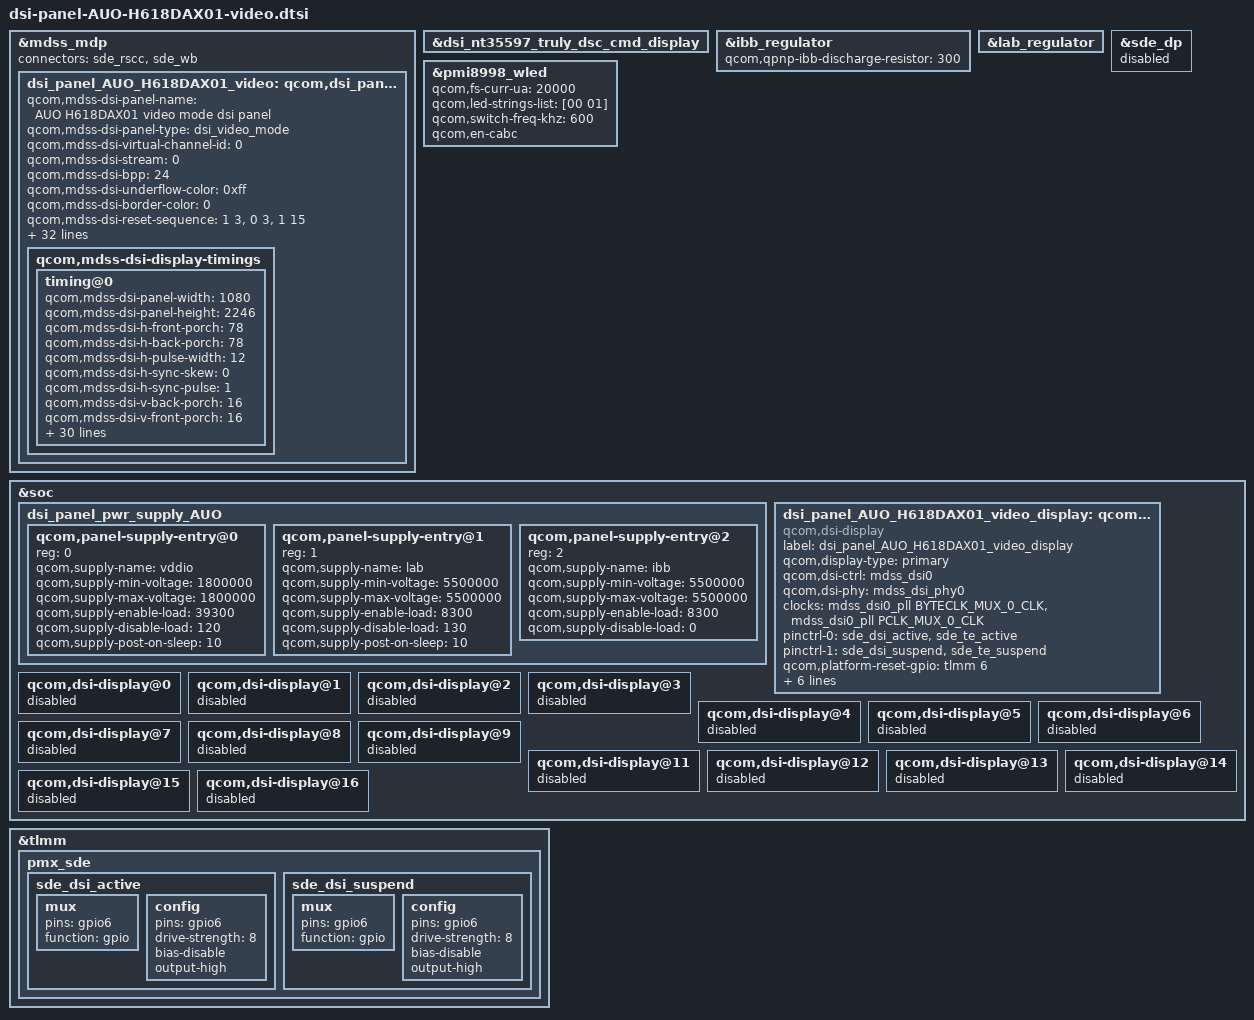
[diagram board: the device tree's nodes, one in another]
/* Copyright (c) 2017, The Linux Foundation. All rights reserved.
 *
 * This program is free software; you can redistribute it and/or modify
 * it under the terms of the GNU General Public License version 2 and
 * only version 2 as published by the Free Software Foundation.
 *
 * This program is distributed in the hope that it will be useful,
 * but WITHOUT ANY WARRANTY; without even the implied warranty of
 * MERCHANTABILITY or FITNESS FOR A PARTICULAR PURPOSE.  See the
 * GNU General Public License for more details.
 */

&mdss_mdp {
	dsi_panel_AUO_H618DAX01_video: qcom,dsi_panel_AUO_H618DAX01_video {
		qcom,mdss-dsi-panel-name =
				"AUO H618DAX01 video mode dsi panel";
		qcom,mdss-dsi-panel-type = "dsi_video_mode";  /* key flag to diff video/cmd, in dsi_panel.c */
		qcom,mdss-dsi-virtual-channel-id = <0>;
		qcom,mdss-dsi-stream = <0>;
		qcom,mdss-dsi-bpp = <24>;
		qcom,mdss-dsi-underflow-color = <0xff>;
		qcom,mdss-dsi-border-color = <0>;
		qcom,mdss-dsi-reset-sequence = <1 3>, <0 3>, <1 15>;  /* >1, >1, >10 */
		qcom,mdss-dsi-traffic-mode = "burst_mode";
		qcom,mdss-dsi-bllp-eof-power-mode;
		qcom,mdss-dsi-bllp-power-mode;
		qcom,mdss-dsi-lane-0-state;
		qcom,mdss-dsi-lane-1-state;
		qcom,mdss-dsi-lane-2-state;
		qcom,mdss-dsi-lane-3-state;
		qcom,mdss-dsi-lp11-init;
		qcom,mdss-dsi-bl-min-level = <1>;
		qcom,mdss-dsi-bl-max-level = <1023>;
		qcom,mdss-dsi-dma-trigger = "trigger_sw";
		qcom,mdss-dsi-mdp-trigger = "none";
		qcom,mdss-dsi-bl-pmic-control-type = "bl_ctrl_dcs";

		qcom,mdss-dsi-tx-eot-append;
		qcom,mdss-dsi-post-init-delay = <1>;

		qcom,mdss-pan-physical-width-dimension = <68>;
		qcom,mdss-pan-physical-height-dimension = <141>;

		qcom,panel-supply-entries = <&dsi_panel_pwr_supply_AUO>;
		qcom,mdss-dsi-mode-sel-gpio-state = "single_port";
		qcom,platform-reset-gpio = <&tlmm 6 0>;
		qcom,platform-te-gpio = <&tlmm 10 0>;
		qcom,mdss-dsi-t-clk-post = <0x0e>;
		qcom,mdss-dsi-t-clk-pre = <0x35>;
		qcom,mdss-dsi-panel-hdr-enabled;
		qcom,mdss-dsi-panel-hdr-color-primaries = <15150 15850 33950 15850 13200 34500 7500 3000>;
		qcom,mdss-dsi-panel-peak-brightness = <5000000>;
		qcom,mdss-dsi-panel-blackness-level = <3300>;
		qcom,ulps-enabled;
		qcom,suspend-ulps-enabled;

		qcom,mdss-dsi-display-timings {
			timing@0{
				qcom,mdss-dsi-panel-width = <1080>;
				qcom,mdss-dsi-panel-height = <2246>;
				qcom,mdss-dsi-h-front-porch = <78>;
				qcom,mdss-dsi-h-back-porch = <78>;
				qcom,mdss-dsi-h-pulse-width = <12>;
				qcom,mdss-dsi-h-sync-skew = <0>;
				qcom,mdss-dsi-h-sync-pulse = <1>;
				qcom,mdss-dsi-v-back-porch = <16>;
				qcom,mdss-dsi-v-front-porch = <16>;
				qcom,mdss-dsi-v-pulse-width = <2>;
				qcom,mdss-dsi-panel-framerate = <60>;
				qcom,mdss-dsi-h-left-border = <0>;
				qcom,mdss-dsi-h-right-border = <0>;
				qcom,mdss-dsi-v-top-border = <0>;
				qcom,mdss-dsi-v-bottom-border = <0>;
				qcom,mdss-dsi-on-command =[
					/* Enable Command2 */
					39 01 00 00 00 00 02 00 00
					39 01 00 00 00 00 04 FF 87 16 01
					/* Enable Focal Command */
					39 01 00 00 00 00 02 00 80
					39 01 00 00 00 00 03 FF 87 16
					/* Resolution 1080x2246  */
					39 01 00 00 00 00 02 00 00
					39 01 00 00 00 00 05 2A 00 00 04 37
					39 01 00 00 00 00 02 00 00
					39 01 00 00 00 00 05 2B 00 00 08 C5
					// PWM Freq. = 34.18K
					39 01 00 00 00 00 02 00 B0
					39 01 00 00 00 00 03 CA 00 00
					// PWM = 10bit
					39 01 00 00 00 00 02 00 B2
					39 01 00 00 00 00 02 CA 04
					// Dimming Frame = 32
					39 01 00 00 00 00 02 00 B5
					39 01 00 00 00 00 02 CA 20
					/* Reload the error OTP Set */
					39 01 00 00 00 00 02 00 80
					39 01 00 00 00 00 10 c0 00 74 00 10 10 00 74 10 10 00 74 00 10 10 00
					39 01 00 00 00 00 02 00 90
					39 01 00 00 00 00 09 CE 00 5C 0B 75 00 5C 00 12
					39 01 00 00 00 00 02 00 B0
					39 01 00 00 00 00 04 CE 04 00 72
					39 01 00 00 00 00 02 00 9B
					39 01 00 00 00 00 04 CE 01 16 07
					// For Desense
					39 01 00 00 00 00 02 00 B0
					39 01 00 00 00 00 05 C5 10 00 00 00
					39 01 00 00 00 00 02 00 C1
					39 01 00 00 00 00 02 C5 44
					39 01 00 00 00 00 02 00 80
					39 01 00 00 00 00 02 C4 41
					39 01 00 00 00 00 02 00 94
					39 01 00 00 00 00 02 C5 66
					39 01 00 00 00 00 02 00 98
					39 01 00 00 00 00 03 C5 56 60
					39 01 00 00 00 00 02 00 88
					39 01 00 00 00 00 03 C3 22 22
					39 01 00 00 00 00 02 00 98
					39 01 00 00 00 00 03 C3 22 22
					39 01 00 00 00 00 02 00 D6
					39 01 00 00 00 00 02 C0 08

					//CABC parameter V51
					39 01 00 00 00 00 02 00 81
					39 01 00 00 00 00 0A CA f0 ff c8 ff b4 ff 00 00 00
					39 01 00 00 00 00 02 00 00
					39 01 00 00 00 00 02 C6 10
					39 01 00 00 00 00 02 00 00
					39 01 00 00 00 00 13 C7 a0 ac ac ba cd aa bb cb ca bb ca ab ab 78 56 34 12 11
					39 01 00 00 00 00 02 00 00
					39 01 00 00 00 00 02 C6 11
					39 01 00 00 00 00 02 00 00
					39 01 00 00 00 00 13 C7 a0 ab 9c ab cc 9b ba cb b9 bb ba bb a9 78 56 34 12 11
					39 01 00 00 00 00 02 00 00
					39 01 00 00 00 00 02 C6 12
					39 01 00 00 00 00 02 00 00
					39 01 00 00 00 00 13 C7 a0 ba 9b aa cc 9a aa cb aa ba ba aa 9a 78 56 34 12 11
					39 01 00 00 00 00 02 00 00
					39 01 00 00 00 00 02 C6 13
					39 01 00 00 00 00 02 00 00
					39 01 00 00 00 00 13 C7 90 ab 9b 9a bc 9b a9 ca 9a aa ab aa a9 78 56 34 12 11
					39 01 00 00 00 00 02 00 00
					39 01 00 00 00 00 02 C6 14
					39 01 00 00 00 00 02 00 00
					39 01 00 00 00 00 13 C7 90 aa 9b a9 ca 9a a9 ba 9a aa ba a9 99 78 56 34 12 11
					39 01 00 00 00 00 02 00 00
					39 01 00 00 00 00 02 C6 15
					39 01 00 00 00 00 02 00 00
					39 01 00 00 00 00 13 C7 90 9a 8b 9a bb 9a 99 ba 9a a8 ca 99 99 88 56 34 12 11
					39 01 00 00 00 00 02 00 00
					39 01 00 00 00 00 02 C6 16
					39 01 00 00 00 00 02 00 00
					39 01 00 00 00 00 13 C7 90 9a 9a 99 ba 9a 98 aa aa 98 ba 8a 89 88 67 45 23 11
					39 01 00 00 00 00 02 00 00
					39 01 00 00 00 00 02 C6 17
					39 01 00 00 00 00 02 00 00
					39 01 00 00 00 00 13 C7 90 99 9a 99 b9 a9 98 a9 aa 88 ba 8a 98 88 78 45 23 22
					39 01 00 00 00 00 02 00 00
					39 01 00 00 00 00 02 C6 18
					39 01 00 00 00 00 02 00 00
					39 01 00 00 00 00 13 C7 80 9a 8a 99 a9 8a 89 a9 9a 98 b9 99 88 88 78 56 34 23
					39 01 00 00 00 00 02 00 00
					39 01 00 00 00 00 02 C6 19
					39 01 00 00 00 00 02 00 00
					39 01 00 00 00 00 13 C7 80 99 8a 89 b9 99 98 a8 a9 88 a9 9a 87 88 88 67 35 33
					39 01 00 00 00 00 02 00 00
					39 01 00 00 00 00 02 C6 1a
					39 01 00 00 00 00 02 00 00
					39 01 00 00 00 00 13 C7 80 99 99 88 a9 99 98 98 a9 79 a9 99 88 88 88 67 45 44
					39 01 00 00 00 00 02 00 00
					39 01 00 00 00 00 02 C6 1b
					39 01 00 00 00 00 02 00 00
					39 01 00 00 00 00 13 C7 80 98 99 89 89 99 89 98 99 79 99 8a 88 88 88 78 56 44
					39 01 00 00 00 00 02 00 00
					39 01 00 00 00 00 02 C6 1c
					39 01 00 00 00 00 02 00 00
					39 01 00 00 00 00 13 C7 80 98 89 89 89 89 89 98 a8 88 98 99 78 88 88 88 57 55
					39 01 00 00 00 00 02 00 00
					39 01 00 00 00 00 02 C6 1d
					39 01 00 00 00 00 02 00 00
					39 01 00 00 00 00 13 C7 A0 88 89 89 98 98 88 98 89 98 97 89 88 88 88 88 67 66
					39 01 00 00 00 00 02 00 00
					39 01 00 00 00 00 02 C6 1e
					39 01 00 00 00 00 02 00 00
					39 01 00 00 00 00 13 C7 A0 88 89 88 88 89 88 98 98 88 88 89 88 88 88 88 78 67
					39 01 00 00 00 00 02 00 00
					39 01 00 00 00 00 02 C6 1f
					39 01 00 00 00 00 02 00 00
					39 01 00 00 00 00 13 C7 70 88 88 88 88 89 88 88 98 87 98 88 88 88 88 88 88 78
					39 01 00 00 00 00 02 00 00
					39 01 00 00 00 00 02 C6 00
					//CABC parameter

					/* Disable Focal Command */
					39 01 00 00 00 00 02 00 00
					39 01 00 00 00 00 04 FF 00 00 00
					/* Disable Command2 */
					39 01 00 00 00 00 02 00 80
					39 01 00 00 00 00 03 FF 00 00
					/* TE enable */
					39 01 00 00 00 00 02 35 00
					// CABC OFF mode
					39 01 00 00 00 00 02 53 24
					39 01 00 00 00 00 02 55 00
					/* Sleep Out, delay > 120ms */
					39 01 00 00 7F 00 01 11
					/* Display on, delay > 30ms*/
					39 01 00 00 1F 00 01 29];
				qcom,mdss-dsi-cabc-on-ui-command = [
					// CMD2 mode on
					39 01 00 00 00 00 02 00 00
					39 01 00 00 00 00 04 FF 87 16 01
					39 01 00 00 00 00 02 00 80
					39 01 00 00 00 00 03 FF 87 16
					// resolution 1080x2246
					39 01 00 00 00 00 02 00 00
					39 01 00 00 00 00 05 2A 00 00 04 37
					39 01 00 00 00 00 02 00 00
					39 01 00 00 00 00 05 2B 00 00 08 C5
					// PWM Freq. = 34.18K
					39 01 00 00 00 00 02 00 B0
					39 01 00 00 00 00 03 CA 00 00
					// PWM = 10bit
					39 01 00 00 00 00 02 00 B2
					39 01 00 00 00 00 02 CA 04
					// Dimming Frame = 32
					39 01 00 00 00 00 02 00 B5
					39 01 00 00 00 00 02 CA 20
					//reload the error OTP set
					39 01 00 00 00 00 02 00 80
					39 01 00 00 00 00 10 c0 00 74 00 10 10 00 74 10 10 00 74 00 10 10 00
					39 01 00 00 00 00 02 00 90
					39 01 00 00 00 00 09 CE 00 5C 0B 75 00 5C 00 12
					39 01 00 00 00 00 02 00 B0
					39 01 00 00 00 00 04 CE 04 00 72
					39 01 00 00 00 00 02 00 9B
					39 01 00 00 00 00 04 CE 01 16 07
					// For Desense
					39 01 00 00 00 00 02 00 B0
					39 01 00 00 00 00 05 C5 10 00 00 00
					39 01 00 00 00 00 02 00 C1
					39 01 00 00 00 00 02 C5 44
					39 01 00 00 00 00 02 00 80
					39 01 00 00 00 00 02 C4 41
					39 01 00 00 00 00 02 00 94
					39 01 00 00 00 00 02 C5 66
					39 01 00 00 00 00 02 00 98
					39 01 00 00 00 00 03 C5 56 60
					39 01 00 00 00 00 02 00 88
					39 01 00 00 00 00 03 C3 22 22
					39 01 00 00 00 00 02 00 98
					39 01 00 00 00 00 03 C3 22 22
					39 01 00 00 00 00 02 00 D6
					39 01 00 00 00 00 02 C0 08
					//CABC parameter V51
					39 01 00 00 00 00 02 00 81
					39 01 00 00 00 00 0A CA f0 ff c8 ff b4 ff 00 00 00
					39 01 00 00 00 00 02 00 00
					39 01 00 00 00 00 02 C6 10
					39 01 00 00 00 00 02 00 00
					39 01 00 00 00 00 13 C7 a0 ac ac ba cd aa bb cb ca bb ca ab ab 78 56 34 12 11
					39 01 00 00 00 00 02 00 00
					39 01 00 00 00 00 02 C6 11
					39 01 00 00 00 00 02 00 00
					39 01 00 00 00 00 13 C7 a0 ab 9c ab cc 9b ba cb b9 bb ba bb a9 78 56 34 12 11
					39 01 00 00 00 00 02 00 00
					39 01 00 00 00 00 02 C6 12
					39 01 00 00 00 00 02 00 00
					39 01 00 00 00 00 13 C7 a0 ba 9b aa cc 9a aa cb aa ba ba aa 9a 78 56 34 12 11
					39 01 00 00 00 00 02 00 00
					39 01 00 00 00 00 02 C6 13
					39 01 00 00 00 00 02 00 00
					39 01 00 00 00 00 13 C7 90 ab 9b 9a bc 9b a9 ca 9a aa ab aa a9 78 56 34 12 11
					39 01 00 00 00 00 02 00 00
					39 01 00 00 00 00 02 C6 14
					39 01 00 00 00 00 02 00 00
					39 01 00 00 00 00 13 C7 90 aa 9b a9 ca 9a a9 ba 9a aa ba a9 99 78 56 34 12 11
					39 01 00 00 00 00 02 00 00
					39 01 00 00 00 00 02 C6 15
					39 01 00 00 00 00 02 00 00
					39 01 00 00 00 00 13 C7 90 9a 8b 9a bb 9a 99 ba 9a a8 ca 99 99 88 56 34 12 11
					39 01 00 00 00 00 02 00 00
					39 01 00 00 00 00 02 C6 16
					39 01 00 00 00 00 02 00 00
					39 01 00 00 00 00 13 C7 90 9a 9a 99 ba 9a 98 aa aa 98 ba 8a 89 88 67 45 23 11
					39 01 00 00 00 00 02 00 00
					39 01 00 00 00 00 02 C6 17
					39 01 00 00 00 00 02 00 00
					39 01 00 00 00 00 13 C7 90 99 9a 99 b9 a9 98 a9 aa 88 ba 8a 98 88 78 45 23 22
					39 01 00 00 00 00 02 00 00
					39 01 00 00 00 00 02 C6 18
					39 01 00 00 00 00 02 00 00
					39 01 00 00 00 00 13 C7 80 9a 8a 99 a9 8a 89 a9 9a 98 b9 99 88 88 78 56 34 23
					39 01 00 00 00 00 02 00 00
					39 01 00 00 00 00 02 C6 19
					39 01 00 00 00 00 02 00 00
					39 01 00 00 00 00 13 C7 80 99 8a 89 b9 99 98 a8 a9 88 a9 9a 87 88 88 67 35 33
					39 01 00 00 00 00 02 00 00
					39 01 00 00 00 00 02 C6 1a
					39 01 00 00 00 00 02 00 00
					39 01 00 00 00 00 13 C7 80 99 99 88 a9 99 98 98 a9 79 a9 99 88 88 88 67 45 44
					39 01 00 00 00 00 02 00 00
					39 01 00 00 00 00 02 C6 1b
					39 01 00 00 00 00 02 00 00
					39 01 00 00 00 00 13 C7 80 98 99 89 89 99 89 98 99 79 99 8a 88 88 88 78 56 44
					39 01 00 00 00 00 02 00 00
					39 01 00 00 00 00 02 C6 1c
					39 01 00 00 00 00 02 00 00
					39 01 00 00 00 00 13 C7 80 98 89 89 89 89 89 98 a8 88 98 99 78 88 88 88 57 55
					39 01 00 00 00 00 02 00 00
					39 01 00 00 00 00 02 C6 1d
					39 01 00 00 00 00 02 00 00
					39 01 00 00 00 00 13 C7 A0 88 89 89 98 98 88 98 89 98 97 89 88 88 88 88 67 66
					39 01 00 00 00 00 02 00 00
					39 01 00 00 00 00 02 C6 1e
					39 01 00 00 00 00 02 00 00
					39 01 00 00 00 00 13 C7 A0 88 89 88 88 89 88 98 98 88 88 89 88 88 88 88 78 67
					39 01 00 00 00 00 02 00 00
					39 01 00 00 00 00 02 C6 1f
					39 01 00 00 00 00 02 00 00
					39 01 00 00 00 00 13 C7 70 88 88 88 88 89 88 88 98 87 98 88 88 88 88 88 88 78
					39 01 00 00 00 00 02 00 00
					39 01 00 00 00 00 02 C6 00
					//CABC parameter

					// CMD2 mode off
					39 01 00 00 00 00 02 00 00
					39 01 00 00 00 00 04 FF 00 00 00
					39 01 00 00 00 00 02 00 80
					39 01 00 00 00 00 03 FF 00 00

					39 01 00 00 00 00 02 35 00
					// CABC ui mode
					39 01 00 00 00 00 02 53 24
					39 01 00 00 00 00 02 55 01
					39 01 00 00 7F 00 01 11
					39 01 00 00 1F 00 01 29];
				qcom,mdss-dsi-cabc-on-still-command = [
					// CMD2 mode on
					39 01 00 00 00 00 02 00 00
					39 01 00 00 00 00 04 FF 87 16 01
					39 01 00 00 00 00 02 00 80
					39 01 00 00 00 00 03 FF 87 16
					// resolution 1080x2246
					39 01 00 00 00 00 02 00 00
					39 01 00 00 00 00 05 2A 00 00 04 37
					39 01 00 00 00 00 02 00 00
					39 01 00 00 00 00 05 2B 00 00 08 C5
					// PWM Freq. = 34.18K
					39 01 00 00 00 00 02 00 B0
					39 01 00 00 00 00 03 CA 00 00
					// PWM = 10bit
					39 01 00 00 00 00 02 00 B2
					39 01 00 00 00 00 02 CA 04
					// Dimming Frame = 32
					39 01 00 00 00 00 02 00 B5
					39 01 00 00 00 00 02 CA 20
					//reload the error OTP set
					39 01 00 00 00 00 02 00 80
					39 01 00 00 00 00 10 c0 00 74 00 10 10 00 74 10 10 00 74 00 10 10 00
					39 01 00 00 00 00 02 00 90
					39 01 00 00 00 00 09 CE 00 5C 0B 75 00 5C 00 12
					39 01 00 00 00 00 02 00 B0
					39 01 00 00 00 00 04 CE 04 00 72
					39 01 00 00 00 00 02 00 9B
					39 01 00 00 00 00 04 CE 01 16 07
					// For Desense
					39 01 00 00 00 00 02 00 B0
					39 01 00 00 00 00 05 C5 10 00 00 00
					39 01 00 00 00 00 02 00 C1
					39 01 00 00 00 00 02 C5 44
					39 01 00 00 00 00 02 00 80
					39 01 00 00 00 00 02 C4 41
					39 01 00 00 00 00 02 00 94
					39 01 00 00 00 00 02 C5 66
					39 01 00 00 00 00 02 00 98
					39 01 00 00 00 00 03 C5 56 60
					39 01 00 00 00 00 02 00 88
					39 01 00 00 00 00 03 C3 22 22
					39 01 00 00 00 00 02 00 98
					39 01 00 00 00 00 03 C3 22 22
					39 01 00 00 00 00 02 00 D6
					39 01 00 00 00 00 02 C0 08
					//CABC parameter V51
					39 01 00 00 00 00 02 00 81
					39 01 00 00 00 00 0A CA f0 ff c8 ff b4 ff 00 00 00
					39 01 00 00 00 00 02 00 00
					39 01 00 00 00 00 02 C6 10
					39 01 00 00 00 00 02 00 00
					39 01 00 00 00 00 13 C7 a0 ac ac ba cd aa bb cb ca bb ca ab ab 78 56 34 12 11
					39 01 00 00 00 00 02 00 00
					39 01 00 00 00 00 02 C6 11
					39 01 00 00 00 00 02 00 00
					39 01 00 00 00 00 13 C7 a0 ab 9c ab cc 9b ba cb b9 bb ba bb a9 78 56 34 12 11
					39 01 00 00 00 00 02 00 00
					39 01 00 00 00 00 02 C6 12
					39 01 00 00 00 00 02 00 00
					39 01 00 00 00 00 13 C7 a0 ba 9b aa cc 9a aa cb aa ba ba aa 9a 78 56 34 12 11
					39 01 00 00 00 00 02 00 00
					39 01 00 00 00 00 02 C6 13
					39 01 00 00 00 00 02 00 00
					39 01 00 00 00 00 13 C7 90 ab 9b 9a bc 9b a9 ca 9a aa ab aa a9 78 56 34 12 11
					39 01 00 00 00 00 02 00 00
					39 01 00 00 00 00 02 C6 14
					39 01 00 00 00 00 02 00 00
					39 01 00 00 00 00 13 C7 90 aa 9b a9 ca 9a a9 ba 9a aa ba a9 99 78 56 34 12 11
					39 01 00 00 00 00 02 00 00
					39 01 00 00 00 00 02 C6 15
					39 01 00 00 00 00 02 00 00
					39 01 00 00 00 00 13 C7 90 9a 8b 9a bb 9a 99 ba 9a a8 ca 99 99 88 56 34 12 11
					39 01 00 00 00 00 02 00 00
					39 01 00 00 00 00 02 C6 16
					39 01 00 00 00 00 02 00 00
					39 01 00 00 00 00 13 C7 90 9a 9a 99 ba 9a 98 aa aa 98 ba 8a 89 88 67 45 23 11
					39 01 00 00 00 00 02 00 00
					39 01 00 00 00 00 02 C6 17
					39 01 00 00 00 00 02 00 00
					39 01 00 00 00 00 13 C7 90 99 9a 99 b9 a9 98 a9 aa 88 ba 8a 98 88 78 45 23 22
					39 01 00 00 00 00 02 00 00
					39 01 00 00 00 00 02 C6 18
					39 01 00 00 00 00 02 00 00
					39 01 00 00 00 00 13 C7 80 9a 8a 99 a9 8a 89 a9 9a 98 b9 99 88 88 78 56 34 23
					39 01 00 00 00 00 02 00 00
					39 01 00 00 00 00 02 C6 19
					39 01 00 00 00 00 02 00 00
					39 01 00 00 00 00 13 C7 80 99 8a 89 b9 99 98 a8 a9 88 a9 9a 87 88 88 67 35 33
					39 01 00 00 00 00 02 00 00
					39 01 00 00 00 00 02 C6 1a
					39 01 00 00 00 00 02 00 00
					39 01 00 00 00 00 13 C7 80 99 99 88 a9 99 98 98 a9 79 a9 99 88 88 88 67 45 44
					39 01 00 00 00 00 02 00 00
					39 01 00 00 00 00 02 C6 1b
					39 01 00 00 00 00 02 00 00
					39 01 00 00 00 00 13 C7 80 98 99 89 89 99 89 98 99 79 99 8a 88 88 88 78 56 44
					39 01 00 00 00 00 02 00 00
					39 01 00 00 00 00 02 C6 1c
					39 01 00 00 00 00 02 00 00
					39 01 00 00 00 00 13 C7 80 98 89 89 89 89 89 98 a8 88 98 99 78 88 88 88 57 55
					39 01 00 00 00 00 02 00 00
					39 01 00 00 00 00 02 C6 1d
					39 01 00 00 00 00 02 00 00
					39 01 00 00 00 00 13 C7 A0 88 89 89 98 98 88 98 89 98 97 89 88 88 88 88 67 66
					39 01 00 00 00 00 02 00 00
					39 01 00 00 00 00 02 C6 1e
					39 01 00 00 00 00 02 00 00
					39 01 00 00 00 00 13 C7 A0 88 89 88 88 89 88 98 98 88 88 89 88 88 88 88 78 67
					39 01 00 00 00 00 02 00 00
					39 01 00 00 00 00 02 C6 1f
					39 01 00 00 00 00 02 00 00
					39 01 00 00 00 00 13 C7 70 88 88 88 88 89 88 88 98 87 98 88 88 88 88 88 88 78
					39 01 00 00 00 00 02 00 00
					39 01 00 00 00 00 02 C6 00
					//CABC parameter

					// CMD2 mode off
					39 01 00 00 00 00 02 00 00
					39 01 00 00 00 00 04 FF 00 00 00
					39 01 00 00 00 00 02 00 80
					39 01 00 00 00 00 03 FF 00 00

					39 01 00 00 00 00 02 35 00
					// CABC still mode
					39 01 00 00 00 00 02 53 24
					39 01 00 00 00 00 02 55 02
					39 01 00 00 7F 00 01 11
					39 01 00 00 1F 00 01 29];
				qcom,mdss-dsi-cabc-on-moving-command = [
					// CMD2 mode on
					39 01 00 00 00 00 02 00 00
					39 01 00 00 00 00 04 FF 87 16 01
					39 01 00 00 00 00 02 00 80
					39 01 00 00 00 00 03 FF 87 16
					// resolution 1080x2246
					39 01 00 00 00 00 02 00 00
					39 01 00 00 00 00 05 2A 00 00 04 37
					39 01 00 00 00 00 02 00 00
					39 01 00 00 00 00 05 2B 00 00 08 C5
					// PWM Freq. = 34.18K
					39 01 00 00 00 00 02 00 B0
					39 01 00 00 00 00 03 CA 00 00
					// PWM = 10bit
					39 01 00 00 00 00 02 00 B2
					39 01 00 00 00 00 02 CA 04
					// Dimming Frame = 32
					39 01 00 00 00 00 02 00 B5
					39 01 00 00 00 00 02 CA 20
					//reload the error OTP set
					39 01 00 00 00 00 02 00 80
					39 01 00 00 00 00 10 c0 00 74 00 10 10 00 74 10 10 00 74 00 10 10 00
					39 01 00 00 00 00 02 00 90
					39 01 00 00 00 00 09 CE 00 5C 0B 75 00 5C 00 12
					39 01 00 00 00 00 02 00 B0
					39 01 00 00 00 00 04 CE 04 00 72
					39 01 00 00 00 00 02 00 9B
					39 01 00 00 00 00 04 CE 01 16 07
					// For Desense
					39 01 00 00 00 00 02 00 B0
					39 01 00 00 00 00 05 C5 10 00 00 00
					39 01 00 00 00 00 02 00 C1
					39 01 00 00 00 00 02 C5 44
					39 01 00 00 00 00 02 00 80
					39 01 00 00 00 00 02 C4 41
					39 01 00 00 00 00 02 00 94
					39 01 00 00 00 00 02 C5 66
					39 01 00 00 00 00 02 00 98
					39 01 00 00 00 00 03 C5 56 60
					39 01 00 00 00 00 02 00 88
					39 01 00 00 00 00 03 C3 22 22
					39 01 00 00 00 00 02 00 98
					39 01 00 00 00 00 03 C3 22 22
					39 01 00 00 00 00 02 00 D6
					39 01 00 00 00 00 02 C0 08
					//CABC parameter V51
					39 01 00 00 00 00 02 00 81
					39 01 00 00 00 00 0A CA f0 ff c8 ff b4 ff 00 00 00
					39 01 00 00 00 00 02 00 00
					39 01 00 00 00 00 02 C6 10
					39 01 00 00 00 00 02 00 00
					39 01 00 00 00 00 13 C7 a0 ac ac ba cd aa bb cb ca bb ca ab ab 78 56 34 12 11
					39 01 00 00 00 00 02 00 00
					39 01 00 00 00 00 02 C6 11
					39 01 00 00 00 00 02 00 00
					39 01 00 00 00 00 13 C7 a0 ab 9c ab cc 9b ba cb b9 bb ba bb a9 78 56 34 12 11
					39 01 00 00 00 00 02 00 00
					39 01 00 00 00 00 02 C6 12
					39 01 00 00 00 00 02 00 00
					39 01 00 00 00 00 13 C7 a0 ba 9b aa cc 9a aa cb aa ba ba aa 9a 78 56 34 12 11
					39 01 00 00 00 00 02 00 00
					39 01 00 00 00 00 02 C6 13
					39 01 00 00 00 00 02 00 00
					39 01 00 00 00 00 13 C7 90 ab 9b 9a bc 9b a9 ca 9a aa ab aa a9 78 56 34 12 11
					39 01 00 00 00 00 02 00 00
					39 01 00 00 00 00 02 C6 14
					39 01 00 00 00 00 02 00 00
					39 01 00 00 00 00 13 C7 90 aa 9b a9 ca 9a a9 ba 9a aa ba a9 99 78 56 34 12 11
					39 01 00 00 00 00 02 00 00
					39 01 00 00 00 00 02 C6 15
					39 01 00 00 00 00 02 00 00
					39 01 00 00 00 00 13 C7 90 9a 8b 9a bb 9a 99 ba 9a a8 ca 99 99 88 56 34 12 11
					39 01 00 00 00 00 02 00 00
					39 01 00 00 00 00 02 C6 16
					39 01 00 00 00 00 02 00 00
					39 01 00 00 00 00 13 C7 90 9a 9a 99 ba 9a 98 aa aa 98 ba 8a 89 88 67 45 23 11
					39 01 00 00 00 00 02 00 00
					39 01 00 00 00 00 02 C6 17
					39 01 00 00 00 00 02 00 00
					39 01 00 00 00 00 13 C7 90 99 9a 99 b9 a9 98 a9 aa 88 ba 8a 98 88 78 45 23 22
					39 01 00 00 00 00 02 00 00
					39 01 00 00 00 00 02 C6 18
					39 01 00 00 00 00 02 00 00
					39 01 00 00 00 00 13 C7 80 9a 8a 99 a9 8a 89 a9 9a 98 b9 99 88 88 78 56 34 23
					39 01 00 00 00 00 02 00 00
					39 01 00 00 00 00 02 C6 19
					39 01 00 00 00 00 02 00 00
					39 01 00 00 00 00 13 C7 80 99 8a 89 b9 99 98 a8 a9 88 a9 9a 87 88 88 67 35 33
					39 01 00 00 00 00 02 00 00
					39 01 00 00 00 00 02 C6 1a
					39 01 00 00 00 00 02 00 00
					39 01 00 00 00 00 13 C7 80 99 99 88 a9 99 98 98 a9 79 a9 99 88 88 88 67 45 44
					39 01 00 00 00 00 02 00 00
					39 01 00 00 00 00 02 C6 1b
					39 01 00 00 00 00 02 00 00
					39 01 00 00 00 00 13 C7 80 98 99 89 89 99 89 98 99 79 99 8a 88 88 88 78 56 44
					39 01 00 00 00 00 02 00 00
					39 01 00 00 00 00 02 C6 1c
					39 01 00 00 00 00 02 00 00
					39 01 00 00 00 00 13 C7 80 98 89 89 89 89 89 98 a8 88 98 99 78 88 88 88 57 55
					39 01 00 00 00 00 02 00 00
					39 01 00 00 00 00 02 C6 1d
					39 01 00 00 00 00 02 00 00
					39 01 00 00 00 00 13 C7 A0 88 89 89 98 98 88 98 89 98 97 89 88 88 88 88 67 66
					39 01 00 00 00 00 02 00 00
					39 01 00 00 00 00 02 C6 1e
					39 01 00 00 00 00 02 00 00
					39 01 00 00 00 00 13 C7 A0 88 89 88 88 89 88 98 98 88 88 89 88 88 88 88 78 67
					39 01 00 00 00 00 02 00 00
					39 01 00 00 00 00 02 C6 1f
					39 01 00 00 00 00 02 00 00
					39 01 00 00 00 00 13 C7 70 88 88 88 88 89 88 88 98 87 98 88 88 88 88 88 88 78
					39 01 00 00 00 00 02 00 00
					39 01 00 00 00 00 02 C6 00
					//CABC parameter

					// CMD2 mode off
					39 01 00 00 00 00 02 00 00
					39 01 00 00 00 00 04 FF 00 00 00
					39 01 00 00 00 00 02 00 80
					39 01 00 00 00 00 03 FF 00 00

					39 01 00 00 00 00 02 35 00
					// CABC moving mode
					39 01 00 00 00 00 02 53 24
					39 01 00 00 00 00 02 55 03
					39 01 00 00 7F 00 01 11
					39 01 00 00 1F 00 01 29];
				qcom,mdss-dsi-on-mp-command =[
					/* Enable Command2 */
					39 01 00 00 00 00 02 00 00
					39 01 00 00 00 00 04 FF 87 16 01
					/* Enable Focal Command */
					39 01 00 00 00 00 02 00 80
					39 01 00 00 00 00 03 FF 87 16
					/* Resolution 1080x2246  */
					39 01 00 00 00 00 02 00 00
					39 01 00 00 00 00 05 2A 00 00 04 37
					39 01 00 00 00 00 02 00 00
					39 01 00 00 00 00 05 2B 00 00 08 C5
					/* Disable Focal Command */
					39 01 00 00 00 00 02 00 00
					39 01 00 00 00 00 04 FF 00 00 00
					/* Disable Command2 */
					39 01 00 00 00 00 02 00 80
					39 01 00 00 00 00 03 FF 00 00
					/* TE enable */
					39 01 00 00 00 00 02 35 00
					// CABC OFF mode
					39 01 00 00 00 00 02 53 24
					39 01 00 00 00 00 02 55 00
					/* Sleep Out, delay > 120ms */
					39 01 00 00 64 00 01 11
					/* Display on, delay > 30ms*/
					39 01 00 00 00 00 01 29];
				qcom,mdss-dsi-cabc-on-ui-mp-command = [
					/* Enable Command2 */
					39 01 00 00 00 00 02 00 00
					39 01 00 00 00 00 04 FF 87 16 01
					/* Enable Focal Command */
					39 01 00 00 00 00 02 00 80
					39 01 00 00 00 00 03 FF 87 16
					// resolution 1080x2246
					39 01 00 00 00 00 02 00 00
					39 01 00 00 00 00 05 2A 00 00 04 37
					39 01 00 00 00 00 02 00 00
					39 01 00 00 00 00 05 2B 00 00 08 C5
					/* Disable Focal Command */
					39 01 00 00 00 00 02 00 00
					39 01 00 00 00 00 04 FF 00 00 00
					/* Disable Command2 */
					39 01 00 00 00 00 02 00 80
					39 01 00 00 00 00 03 FF 00 00
					/* TE enable */
					39 01 00 00 00 00 02 35 00
					// CABC ui mode
					39 01 00 00 00 00 02 53 24
					39 01 00 00 00 00 02 55 01
					39 01 00 00 64 00 01 11
					39 01 00 00 00 00 01 29];
				qcom,mdss-dsi-cabc-on-still-mp-command = [
					/* Enable Command2 */
					39 01 00 00 00 00 02 00 00
					39 01 00 00 00 00 04 FF 87 16 01
					/* Enable Focal Command */
					39 01 00 00 00 00 02 00 80
					39 01 00 00 00 00 03 FF 87 16
					// resolution 1080x2246
					39 01 00 00 00 00 02 00 00
					39 01 00 00 00 00 05 2A 00 00 04 37
					39 01 00 00 00 00 02 00 00
					39 01 00 00 00 00 05 2B 00 00 08 C5
					/* Disable Focal Command */
					39 01 00 00 00 00 02 00 00
					39 01 00 00 00 00 04 FF 00 00 00
					/* Disable Command2 */
					39 01 00 00 00 00 02 00 80
					39 01 00 00 00 00 03 FF 00 00
					/* TE enable */
					39 01 00 00 00 00 02 35 00
					// CABC still mode
					39 01 00 00 00 00 02 53 24
					39 01 00 00 00 00 02 55 02
					39 01 00 00 64 00 01 11
					39 01 00 00 00 00 01 29];
				qcom,mdss-dsi-cabc-on-moving-mp-command = [
					/* Enable Command2 */
					39 01 00 00 00 00 02 00 00
					39 01 00 00 00 00 04 FF 87 16 01
					/* Enable Focal Command */
					39 01 00 00 00 00 02 00 80
					39 01 00 00 00 00 03 FF 87 16
					// resolution 1080x2246
					39 01 00 00 00 00 02 00 00
					39 01 00 00 00 00 05 2A 00 00 04 37
					39 01 00 00 00 00 02 00 00
					39 01 00 00 00 00 05 2B 00 00 08 C5
					/* Disable Focal Command */
					39 01 00 00 00 00 02 00 00
					39 01 00 00 00 00 04 FF 00 00 00
					/* Disable Command2 */
					39 01 00 00 00 00 02 00 80
					39 01 00 00 00 00 03 FF 00 00
					/* TE enable */
					39 01 00 00 00 00 02 35 00
					// CABC moving mode
					39 01 00 00 00 00 02 53 24
					39 01 00 00 00 00 02 55 03
					39 01 00 00 64 00 01 11
					39 01 00 00 00 00 01 29];
				qcom,mdss-dsi-off-command = [
					05 01 00 00 20 00 02 28 00
					05 01 00 00 78 00 02 10 00
					15 01 00 00 00 00 02 00 00
					39 01 00 00 00 00 05 F7 5A A5 87 16];
				qcom,mdss-dsi-on-command-state = "dsi_lp_mode";
				qcom,mdss-dsi-off-command-state = "dsi_lp_mode";

				qcom,mdss-dsi-panel-phy-timings = [00 22 09 09 25 23 09 09 06 03 04 00];
				qcom,display-topology = <1 0 1>;     /* reffer non-dsc */
				qcom,default-topology-index = <0>;
			};
		};
	};
};

&dsi_nt35597_truly_dsc_cmd_display {
	/delete-property/ qcom,dsi-display-active;
};

&ibb_regulator {
	/delete-property/ qcom,qpnp-ibb-use-default-voltage;
	qcom,qpnp-ibb-discharge-resistor = <300>;

};

&lab_regulator {
	/delete-property/ qcom,qpnp-lab-use-default-voltage;
};

&sde_dp {
	status = "disabled";
};

&pmi8998_wled {
	qcom,fs-curr-ua = <20000>;
	qcom,led-strings-list = [00 01];
	qcom,switch-freq-khz = <600>;
	qcom,en-cabc;
};


&mdss_mdp {
	connectors = <&sde_rscc &sde_wb>;
};

#include <dt-bindings/gpio/gpio.h>
#include <dt-bindings/regulator/qcom,rpmh-regulator.h>
&soc {
	dsi_panel_pwr_supply_AUO: dsi_panel_pwr_supply_AUO {
		#address-cells = <1>;
		#size-cells = <0>;

		qcom,panel-supply-entry@0 {
			reg = <0>;
			qcom,supply-name = "vddio";
			qcom,supply-min-voltage = <1800000>;
			qcom,supply-max-voltage = <1800000>;
			qcom,supply-enable-load = <39300>;
			qcom,supply-disable-load = <120>;
			qcom,supply-post-on-sleep = <10>;
		};

		qcom,panel-supply-entry@1 {
			reg = <1>;
			qcom,supply-name = "lab";
			qcom,supply-min-voltage = <5500000>;
			qcom,supply-max-voltage = <5500000>;
			qcom,supply-enable-load = <8300>;
			qcom,supply-disable-load = <130>;
			qcom,supply-post-on-sleep = <10>;	/* sleep > 10ms before power on */
		};

		qcom,panel-supply-entry@2 {
			reg = <2>;
			qcom,supply-name = "ibb";
			qcom,supply-min-voltage = <5500000>;
			qcom,supply-max-voltage = <5500000>;
			qcom,supply-enable-load = <8300>;
			qcom,supply-disable-load = <0>;
		};
	};

	dsi_panel_AUO_H618DAX01_video_display: qcom,dsi-display@17 {
		compatible = "qcom,dsi-display";
		label = "dsi_panel_AUO_H618DAX01_video_display";
		qcom,display-type = "primary";

		qcom,dsi-ctrl = <&mdss_dsi0>;
		qcom,dsi-phy = <&mdss_dsi_phy0>;
		clocks = <&mdss_dsi0_pll BYTECLK_MUX_0_CLK>,
			<&mdss_dsi0_pll PCLK_MUX_0_CLK>;
		clock-names = "src_byte_clk", "src_pixel_clk";

		pinctrl-names = "panel_active", "panel_suspend";
		pinctrl-0 = <&sde_dsi_active &sde_te_active>;
		pinctrl-1 = <&sde_dsi_suspend &sde_te_suspend>;
		qcom,platform-reset-gpio = <&tlmm 6 0>;
		qcom,platform-te-gpio = <&tlmm 10 0>;

		qcom,dsi-panel = <&dsi_panel_AUO_H618DAX01_video>;
		vddio-supply = <&pm8998_l14>;
		lab-supply = <&lab_regulator>;
		ibb-supply = <&ibb_regulator>;

		qcom,dsi-display-active;
	};

	qcom,dsi-display@0 {
		status = "disabled";
	};

	qcom,dsi-display@1 {
		status = "disabled";
	};

	qcom,dsi-display@2 {
		status = "disabled";
	};

	qcom,dsi-display@3 {
		status = "disabled";
	};

	qcom,dsi-display@4 {
		status = "disabled";
	};

	qcom,dsi-display@5 {
		status = "disabled";
	};

	qcom,dsi-display@6 {
		status = "disabled";
	};

	qcom,dsi-display@7 {
		status = "disabled";
	};

	qcom,dsi-display@8 {
		status = "disabled";
	};

	qcom,dsi-display@9 {
		status = "disabled";
	};

	qcom,dsi-display@11 {
		status = "disabled";
	};

	qcom,dsi-display@12 {
		status = "disabled";
	};

	qcom,dsi-display@13 {
		status = "disabled";
	};

	qcom,dsi-display@14 {
		status = "disabled";
	};

	qcom,dsi-display@15 {
		status = "disabled";
	};

	qcom,dsi-display@16 {
		status = "disabled";
	};
};

&tlmm {
	pmx_sde: pmx_sde {
		sde_dsi_active: sde_dsi_active {
			mux {
				pins = "gpio6";
				function = "gpio";
			};

			config {
				pins = "gpio6";
				drive-strength = <8>;   /* 8 mA */
				bias-disable;
				output-high;
			};
		};
		sde_dsi_suspend: sde_dsi_suspend {
			mux {
				pins = "gpio6";
				function = "gpio";
			};

			config {
				pins = "gpio6";
				drive-strength = <8>;   /* 8 mA */
				bias-disable;
				output-high;
			};
		};
	};
};
